# STM32H743 register map
File version: 2.4
CPU: CM7 r0p1, little endian, MPU, FPU, 4 interrupt priority bits
Registers are 32-bit, read-write, reset 0x0 unless marked. A register's access mark holds for its fields unless they carry their own. Offsets are from the block's base; [hi:lo] are bit positions; {n}, {i} and the like mark numbered series; 'fields as' and 'values as' point back to an identical list.

## OTG1_HS_HOST — USB 1 OTG 高速接口
Base 0x40040400
Same registers: OTG2_HS_HOST 0x40080400
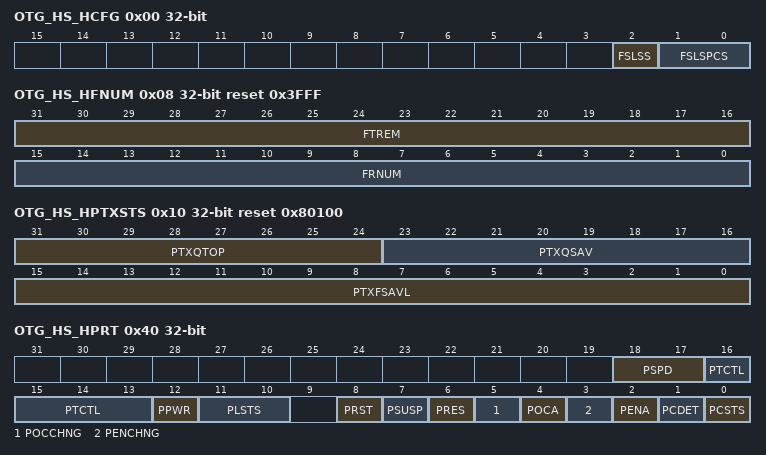
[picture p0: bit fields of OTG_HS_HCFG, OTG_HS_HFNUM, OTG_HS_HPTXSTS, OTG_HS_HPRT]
0x00 OTG_HS_HCFG access per field — OTG_HS 主机配置寄存器
  [2] FSLSS ro — 仅支持 FS 和 LS
  [1:0] FSLSPCS rw — FS/LS PHY 时钟选择
0x04 OTG_HS_HFIR reset 0xEA60 — OTG_HS 主机帧间隔寄存器
  [15:0] FRIVL — 帧间隔
0x08 OTG_HS_HFNUM ro reset 0x3FFF — OTG_HS 主机帧编号/帧剩余时间寄存器
  [31:16] FTREM — 帧剩余时间
  [15:0] FRNUM — 帧编号
0x10 OTG_HS_HPTXSTS access per field reset 0x80100 — OTG_HS 主机周期发送 FIFO/队列状态寄存器
  [31:24] PTXQTOP ro — 周期发送请求队列顶部
  [23:16] PTXQSAV ro — 周期发送请求队列可用空间
  [15:0] PTXFSAVL rw — 周期发送数据 FIFO 可用空间
0x14 OTG_HS_HAINT ro — OTG_HS 主机全通道中断寄存器
  [15:0] HAINT — 通道中断
0x18 OTG_HS_HAINTMSK — OTG_HS 主机全通道中断屏蔽寄存器
  [15:0] HAINTM — 通道中断屏蔽
0x40 OTG_HS_HPRT access per field — OTG_HS 主机端口控制与状态寄存器
  [18:17] PSPD ro — 端口速度
  [16:13] PTCTL rw — 端口测试控制
  [12] PPWR rw — 端口供电
  [11:10] PLSTS ro — 端口线路状态
  [8] PRST rw — 端口复位
  [7] PSUSP rw — 端口挂起
  [6] PRES rw — 端口恢复
  [5] POCCHNG rw — 端口过流变更
  [4] POCA ro — 端口过流激活
  [3] PENCHNG rw — 端口使能/禁用变更
  [2] PENA rw — 端口使能
  [1] PCDET rw — 端口连接检测到
  [0] PCSTS ro — 端口连接状态
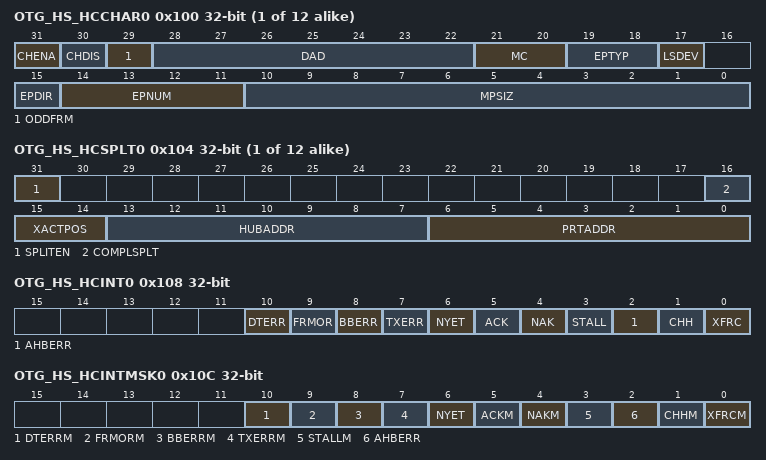
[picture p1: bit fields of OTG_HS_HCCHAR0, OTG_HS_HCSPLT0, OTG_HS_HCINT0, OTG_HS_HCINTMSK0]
{0x100+0x20*i} OTG_HS_HCCHAR{i} (i=0..11) — OTG_HS 主机通道-{i} 特性寄存器
  [31] CHENA — 通道使能
  [30] CHDIS — 通道禁用
  [29] ODDFRM — 奇数帧
  [28:22] DAD — 设备地址
  [21:20] MC — 多重计数 (MC) / 错误计数 (EC)
  [19:18] EPTYP — 端点类型
  [17] LSDEV — 低速设备
  [15] EPDIR — 端点方向
  [14:11] EPNUM — 端点编号
  [10:0] MPSIZ — 最大数据包长度
{0x104+0x20*i} OTG_HS_HCSPLT{i} (i=0..11) — OTG_HS 主机通道-{i} 拆分控制寄存器
  [31] SPLITEN — 拆分使能
  [16] COMPLSPLT — 执行完整拆分
  [15:14] XACTPOS
  [13:7] HUBADDR — 集线器地址
  [6:0] PRTADDR — 端口地址
0x108 OTG_HS_HCINT0 — OTG_HS 主机通道-11 中断寄存器
  [10] DTERR — 数据翻转错误
  [9] FRMOR — 帧溢出
  [8] BBERR — 总线混乱错误
  [7] TXERR — 事务错误
  [6] NYET — 收到应答中断
  [5] ACK — 收到/发送 ACK 应答中断
  [4] NAK — 收到 NAK 应答中断
  [3] STALL — 收到 STALL 应答中断
  [2] AHBERR — AHB 错误
  [1] CHH — 通道暂停
  [0] XFRC — 传输完成
0x10C OTG_HS_HCINTMSK0 — OTG_HS 主机通道-11 中断屏蔽寄存器
  [10] DTERRM — 数据翻转错误中断屏蔽
  [9] FRMORM — 帧溢出中断屏蔽
  [8] BBERRM — 总线混乱错误中断屏蔽
  [7] TXERRM — 事务错误中断屏蔽
  [6] NYET — 应答接收中断屏蔽
  [5] ACKM — ACK 应答接收/发送中断屏蔽
  [4] NAKM — NAK 应答接收中断屏蔽
  [3] STALLM — STALL 应答接收中断屏蔽
  [2] AHBERR — AHB 错误
  [1] CHHM — 通道暂停中断屏蔽
  [0] XFRCM — 传输完成中断屏蔽
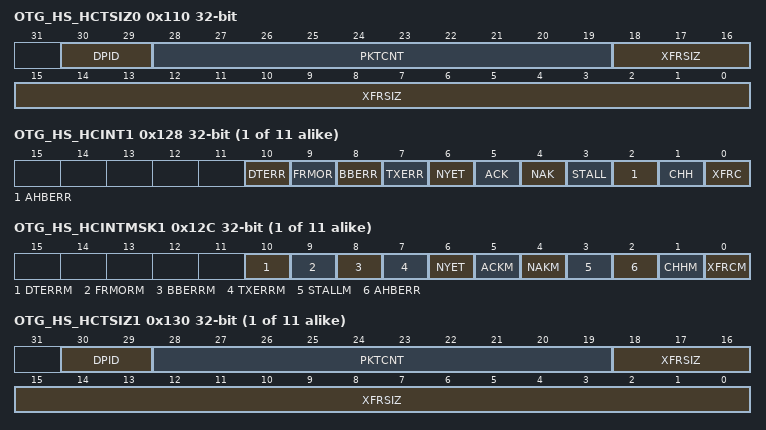
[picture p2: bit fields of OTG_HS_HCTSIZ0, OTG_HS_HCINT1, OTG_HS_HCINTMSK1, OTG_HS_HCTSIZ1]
0x110 OTG_HS_HCTSIZ0 — OTG_HS 主机通道-11 传输大小寄存器
  [30:29] DPID — 数据 PID
  [28:19] PKTCNT — 数据包数量
  [18:0] XFRSIZ — 传输大小
{0x114+0x20*i} OTG_HS_HCDMA{i} (i=0..11) — OTG_HS 主机通道-{i} DMA 地址寄存器
  [31:0] DMAADDR — DMA 地址
{0x108+0x20*i} OTG_HS_HCINT{i} (i=1..11) — OTG_HS 主机通道-{i} 中断寄存器
  fields as OTG_HS_HCINT0
{0x10C+0x20*i} OTG_HS_HCINTMSK{i} (i=1..11) — OTG_HS 主机通道-{i} 中断屏蔽寄存器
  fields as OTG_HS_HCINTMSK0
{0x110+0x20*i} OTG_HS_HCTSIZ{i} (i=1..11) — OTG_HS 主机通道-{i} 传输大小寄存器
  fields as OTG_HS_HCTSIZ0
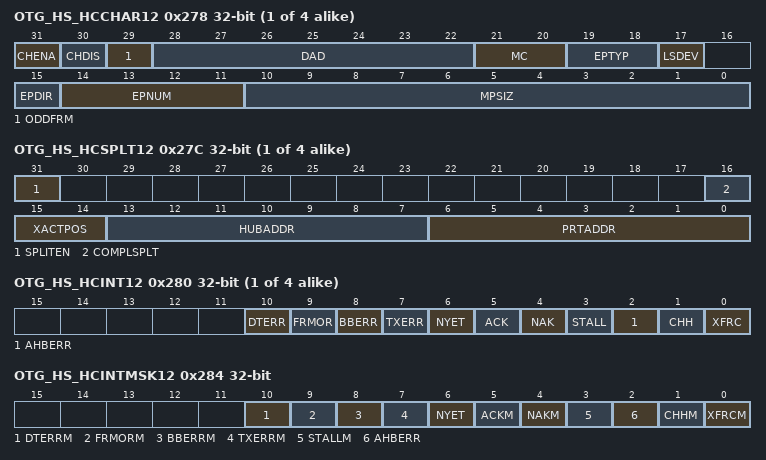
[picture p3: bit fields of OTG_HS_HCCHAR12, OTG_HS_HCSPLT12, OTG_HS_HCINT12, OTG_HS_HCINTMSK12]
{0x158+0x18*i} OTG_HS_HCCHAR{i} (i=12..15) — OTG_HS 主机通道-{i} 特性寄存器
  fields as OTG_HS_HCCHAR0
{0x15C+0x18*i} OTG_HS_HCSPLT{i} (i=12..15) — OTG_HS 主机通道-{i} 拆分控制寄存器
  fields as OTG_HS_HCSPLT0
{0x160+0x18*i} OTG_HS_HCINT{i} (i=12..15) — OTG_HS 主机通道-{i} 中断寄存器
  fields as OTG_HS_HCINT0
0x284 OTG_HS_HCINTMSK12 — OTG_HS 主机通道-12 中断屏蔽寄存器
  [10] DTERRM — 数据翻转错误中断屏蔽
  [9] FRMORM — 帧溢出中断屏蔽
  [8] BBERRM — 总线混乱错误
  [7] TXERRM — 事务错误
  [6] NYET — 收到应答中断
  [5] ACKM — ACK 应答接收/发送中断屏蔽
  [4] NAKM — NAK 应答接收中断屏蔽
  [3] STALLM — STALL 应答接收中断屏蔽
  [2] AHBERR — AHB 错误
  [1] CHHM — 通道暂停中断屏蔽
  [0] XFRCM — 传输完成中断屏蔽
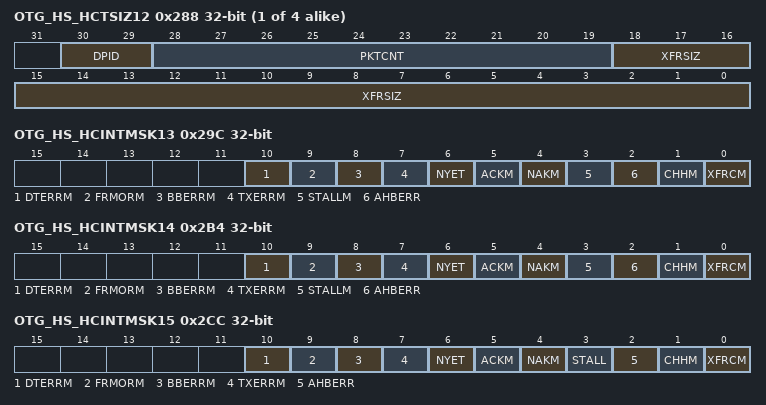
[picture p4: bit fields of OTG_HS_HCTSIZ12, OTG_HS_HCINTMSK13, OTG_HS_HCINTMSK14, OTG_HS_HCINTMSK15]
{0x168+0x18*i} OTG_HS_HCTSIZ{i} (i=12..15) — OTG_HS 主机通道-{i} 传输大小寄存器
  fields as OTG_HS_HCTSIZ0
{0x16C+0x18*i} OTG_HS_HCDMA{i} (i=12..15) — OTG_HS 主机通道-{i} DMA 地址寄存器
  [31:0] DMAADDR — DMA 地址
0x29C OTG_HS_HCINTMSK13 — OTG_HS 主机通道-13 中断屏蔽寄存器
  [10] DTERRM — 数据翻转错误中断屏蔽
  [9] FRMORM — 帧溢出中断屏蔽
  [8] BBERRM — 总线混乱错误
  [7] TXERRM — 事务错误
  [6] NYET — 收到应答中断
  [5] ACKM — ACK 应答接收/发送中断屏蔽
  [4] NAKM — NAK 应答接收中断屏蔽
  [3] STALLM — STALLM 应答接收中断屏蔽
  [2] AHBERR — AHB 错误
  [1] CHHM — 通道暂停中断屏蔽
  [0] XFRCM — 传输完成中断屏蔽
0x2B4 OTG_HS_HCINTMSK14 — OTG_HS 主机通道-14 中断屏蔽寄存器
  [10] DTERRM — 数据翻转错误中断屏蔽
  [9] FRMORM — 帧溢出中断屏蔽
  [8] BBERRM — 总线混乱错误
  [7] TXERRM — 事务错误
  [6] NYET — 收到应答中断
  [5] ACKM — ACKM 应答接收/发送中断屏蔽
  [4] NAKM — NAKM 应答接收中断屏蔽
  [3] STALLM — STALL 应答接收中断屏蔽
  [2] AHBERR — AHB 错误
  [1] CHHM — 通道暂停中断屏蔽
  [0] XFRCM — 传输完成中断屏蔽
0x2CC OTG_HS_HCINTMSK15 — OTG_HS 主机通道-15 中断屏蔽寄存器
  [10] DTERRM — 数据翻转错误中断屏蔽
  [9] FRMORM — 帧溢出中断屏蔽
  [8] BBERRM — 总线混乱错误
  [7] TXERRM — 事务错误
  [6] NYET — 收到应答中断
  [5] ACKM — ACK 应答接收/发送中断屏蔽
  [4] NAKM — NAK 应答接收中断屏蔽
  [3] STALL — STALL 应答接收中断屏蔽
  [2] AHBERR — AHB 错误
  [1] CHHM — 通道暂停中断屏蔽
  [0] XFRCM — 传输完成中断屏蔽
